# RP2350 register map
Vendor: Raspberry Pi; Series: RP; File version: 0.1
CPU: CM33 r1p0, little endian, MPU, FPU, DSP, VTOR, 4 interrupt priority bits, 52 interrupts, 8 SAU regions
Registers are 32-bit, read-write, reset 0x0 unless marked. A register's access mark holds for its fields unless they carry their own. Offsets are from the block's base; [hi:lo] are bit positions; {n}, {i} and the like mark numbered series.

## PLL_SYS — Peripheral description
Base 0x40050000
Same registers: PLL_USB 0x40058000
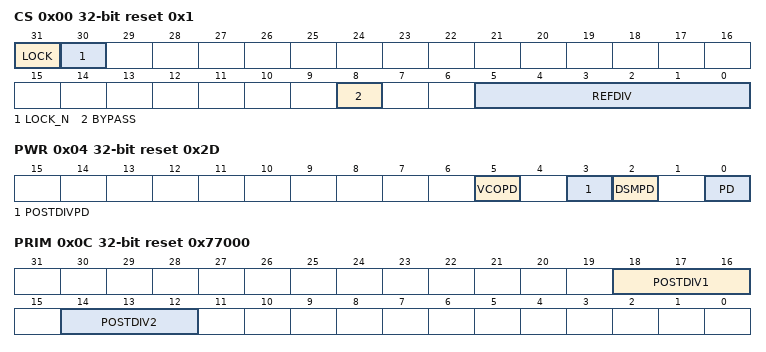
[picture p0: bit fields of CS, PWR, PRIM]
0x00 CS reset 0x1 — Control and Status GENERAL CONSTRAINTS: Reference clock frequency min=5MHz, max=800MHz Feedback divider min=16, max=320 VCO frequency min=750MHz, max=1600MHz
  [31] LOCK ro — PLL is locked
  [30] LOCK_N write-1-clears — PLL is not locked Ideally this is cleared when PLL lock is seen and this should never normally be set
  [8] BYPASS — Passes the reference clock to the output instead of the divided VCO. The VCO continues to run so the user can switch between the reference clock and the divided VCO but the output will glitch when doing so.
  [5:0] REFDIV — Divides the PLL input reference clock. Behaviour is undefined for div=0. PLL output will be unpredictable during refdiv changes, wait for lock=1 before using it.
0x04 PWR reset 0x2D — Controls the PLL power modes.
  [5] VCOPD — PLL VCO powerdown To save power set high when PLL output not required or bypass=1.
  [3] POSTDIVPD — PLL post divider powerdown To save power set high when PLL output not required or bypass=1.
  [2] DSMPD — PLL DSM powerdown Nothing is achieved by setting this low.
  [0] PD — PLL powerdown To save power set high when PLL output not required.
0x08 FBDIV_INT — Feedback divisor (note: this PLL does not support fractional division)
  [11:0] FBDIV_INT — see ctrl reg description for constraints
0x0C PRIM reset 0x77000 — Controls the PLL post dividers for the primary output (note: this PLL does not have a secondary output) the primary output is driven from VCO divided by postdiv1*postdiv2
  [18:16] POSTDIV1 — divide by 1-7
  [14:12] POSTDIV2 — divide by 1-7
0x10 INTR — Raw Interrupts
  [0] LOCK_N_STICKY write-1-clears — Pre-defined description
0x14 INTE — Interrupt Enable
  [0] LOCK_N_STICKY — Pre-defined description
0x18 INTF — Interrupt Force
  [0] LOCK_N_STICKY — Pre-defined description
0x1C INTS — Interrupt status after masking & forcing
  [0] LOCK_N_STICKY ro — Pre-defined description

## WATCHDOG — Peripheral description
Base 0x400D8000
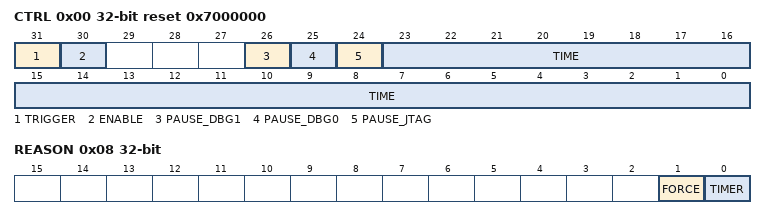
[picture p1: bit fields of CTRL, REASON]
0x00 CTRL reset 0x7000000 — Watchdog control The rst_wdsel register determines which subsystems are reset when the watchdog is triggered. The watchdog can be triggered in software.
  [31] TRIGGER wo — Trigger a watchdog reset
  [30] ENABLE — When not enabled the watchdog timer is paused
  [26] PAUSE_DBG1 — Pause the watchdog timer when processor 1 is in debug mode
  [25] PAUSE_DBG0 — Pause the watchdog timer when processor 0 is in debug mode
  [24] PAUSE_JTAG — Pause the watchdog timer when JTAG is accessing the bus fabric
  [23:0] TIME ro — Indicates the time in usec before a watchdog reset will be triggered
0x04 LOAD — Load the watchdog timer. The maximum setting is 0xffffff which corresponds to approximately 16 seconds.
  [23:0] LOAD wo — Pre-defined description
0x08 REASON — Logs the reason for the last reset. Both bits are zero for the case of a hardware reset. Additionally, as of RP2350, a debugger warm reset of either core (SYSRESETREQ or hartreset) will also clear the watchdog reason register, so that software loaded under the debugger following a watchdog timeout will not continue to see the timeout condition.
  [1] FORCE ro — Pre-defined description
  [0] TIMER ro — Pre-defined description
{0xC+4i} SCRATCH{i} (i=0..7) — Scratch register. Information persists through soft reset of the chip.
  [31:0] SCRATCH{i} — Pre-defined description

## TIMER0 — Controls time and alarms time is a 64 bit value indicating the time since power-on timeh is the top 32 bits of time & timel is the bottom 32 bits to change time write to timelw before timehw to read time read from timelr before timehr An alarm is set by setting alarm_enable and writing to the corresponding alarm register When an alarm is pending, the corresponding alarm_running signal will be high An alarm can be cancelled before it has finished by clearing the alarm_enable When an alarm fires, the corresponding alarm_irq is set and alarm_running is cleared To clear the interrupt write a 1 to the corresponding alarm_irq The timer can be locked to prevent writing
Base 0x400B0000
Same registers: TIMER1 0x400B8000
0x00 TIMEHW — Write to bits 63:32 of time always write timelw before timehw
  [31:0] TIMEHW wo — Pre-defined description
0x04 TIMELW — Write to bits 31:0 of time writes do not get copied to time until timehw is written
  [31:0] TIMELW wo — Pre-defined description
0x08 TIMEHR — Read from bits 63:32 of time always read timelr before timehr
  [31:0] TIMEHR ro — Pre-defined description
0x0C TIMELR — Read from bits 31:0 of time
  [31:0] TIMELR ro read-modifies — Pre-defined description
{0x10+4i} ALARM{i} (i=0..3) — Arm alarm {i}, and configure the time it will fire. Once armed, the alarm fires when TIMER_ALARM{i} == TIMELR. The alarm will disarm itself once it fires, and can be disarmed early using the ARMED status register.
  [31:0] ALARM{i} — Pre-defined description
0x20 ARMED — Indicates the armed/disarmed status of each alarm. A write to the corresponding ALARMx register arms the alarm. Alarms automatically disarm upon firing, but writing ones here will disarm immediately without waiting to fire.
  [3:0] ARMED write-1-clears — Pre-defined description
0x24 TIMERAWH — Raw read from bits 63:32 of time (no side effects)
  [31:0] TIMERAWH ro — Pre-defined description
0x28 TIMERAWL — Raw read from bits 31:0 of time (no side effects)
  [31:0] TIMERAWL ro — Pre-defined description
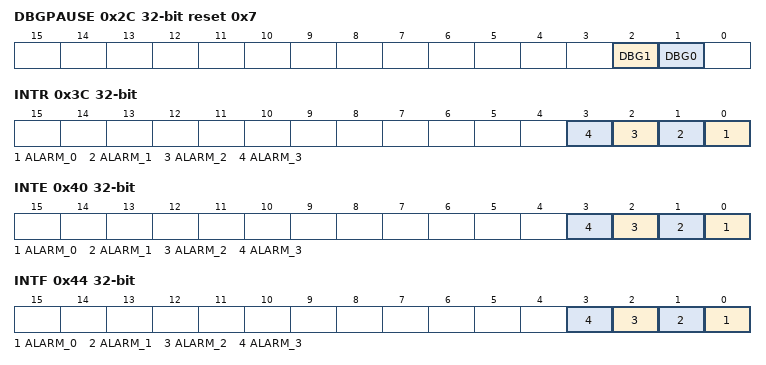
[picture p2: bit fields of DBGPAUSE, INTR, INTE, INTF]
0x2C DBGPAUSE reset 0x7 — Set bits high to enable pause when the corresponding debug ports are active
  [2] DBG1 — Pause when processor 1 is in debug mode
  [1] DBG0 — Pause when processor 0 is in debug mode
0x30 PAUSE — Set high to pause the timer
  [0] PAUSE — Pre-defined description
0x34 LOCKED — Set locked bit to disable write access to timer Once set, cannot be cleared (without a reset)
  [0] LOCKED — Pre-defined description
0x38 SOURCE — Selects the source for the timer. Defaults to the normal tick configured in the ticks block (typically configured to 1 microsecond). Writing to 1 will ignore the tick and count clk_sys cycles instead.
  [0] CLK_SYS — Pre-defined description
    0=TICK; 1=CLK_SYS
0x3C INTR — Raw Interrupts
  [n] ALARM_{n} write-1-clears (n=0..3) — Pre-defined description
0x40 INTE — Interrupt Enable
  [n] ALARM_{n} (n=0..3) — Pre-defined description
0x44 INTF — Interrupt Force
  [n] ALARM_{n} (n=0..3) — Pre-defined description
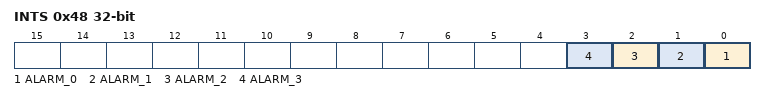
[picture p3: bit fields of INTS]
0x48 INTS — Interrupt status after masking & forcing
  [n] ALARM_{n} ro (n=0..3) — Pre-defined description
